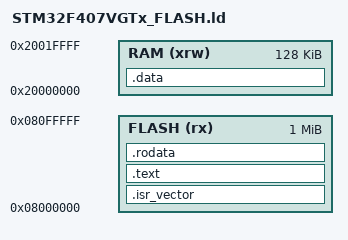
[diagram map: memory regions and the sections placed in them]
/*
******************************************************************************
**

**  File        : LinkerScript.ld
**
**  Author		: Auto-generated by System Workbench for STM32
**
**  Abstract    : Linker script for STM32F407VGTx series
**                1024Kbytes FLASH and 192Kbytes RAM
**
**                Set heap size, stack size and stack location according
**                to application requirements.
**
**                Set memory bank area and size if external memory is used.
**
**  Target      : STMicroelectronics STM32
**
**  Distribution: The file is distributed “as is,” without any warranty
**                of any kind.
**
*****************************************************************************
** @attention
**
** <h2><center>&copy; COPYRIGHT(c) 2020 Jonathan Dukes, jdukes@tcd.ie</center></h2>
** <h2><center>&copy; COPYRIGHT(c) 2019 STMicroelectronics</center></h2>
**
** Redistribution and use in source and binary forms, with or without modification,
** are permitted provided that the following conditions are met:
**   1. Redistributions of source code must retain the above copyright notice,
**      this list of conditions and the following disclaimer.
**   2. Redistributions in binary form must reproduce the above copyright notice,
**      this list of conditions and the following disclaimer in the documentation
**      and/or other materials provided with the distribution.
**   3. Neither the name of STMicroelectronics nor the names of its contributors
**      may be used to endorse or promote products derived from this software
**      without specific prior written permission.
**
** THIS SOFTWARE IS PROVIDED BY THE COPYRIGHT HOLDERS AND CONTRIBUTORS "AS IS"
** AND ANY EXPRESS OR IMPLIED WARRANTIES, INCLUDING, BUT NOT LIMITED TO, THE
** IMPLIED WARRANTIES OF MERCHANTABILITY AND FITNESS FOR A PARTICULAR PURPOSE ARE
** DISCLAIMED. IN NO EVENT SHALL THE COPYRIGHT HOLDER OR CONTRIBUTORS BE LIABLE
** FOR ANY DIRECT, INDIRECT, INCIDENTAL, SPECIAL, EXEMPLARY, OR CONSEQUENTIAL
** DAMAGES (INCLUDING, BUT NOT LIMITED TO, PROCUREMENT OF SUBSTITUTE GOODS OR
** SERVICES; LOSS OF USE, DATA, OR PROFITS; OR BUSINESS INTERRUPTION) HOWEVER
** CAUSED AND ON ANY THEORY OF LIABILITY, WHETHER IN CONTRACT, STRICT LIABILITY,
** OR TORT (INCLUDING NEGLIGENCE OR OTHERWISE) ARISING IN ANY WAY OUT OF THE USE
** OF THIS SOFTWARE, EVEN IF ADVISED OF THE POSSIBILITY OF SUCH DAMAGE.
**
*****************************************************************************
*/

ENTRY(Reset_Handler)

_estack = 0x20020000;       /* end of RAM */
_Min_Stack_Size = 0x400;    /* required amount of stack */

MEMORY
{
RAM (xrw)       : ORIGIN = 0x20000000, LENGTH = 128K
FLASH (rx)      : ORIGIN = 0x08000000, LENGTH = 1024K
}

SECTIONS
{
  /* The startup code goes first into FLASH */
  .isr_vector :
  {
    . = ALIGN(4);
    KEEP(*(.isr_vector))
    . = ALIGN(4);
  } >FLASH

  /* The program code and other data goes into FLASH */
  .text :
  {
    . = ALIGN(4);
    *(.text)           /* .text sections (code) */
    . = ALIGN(4);
    _etext = .;        /* define a global symbols at end of code */
  } >FLASH

  /* Constant data goes into FLASH */
  .rodata :
  {
    . = ALIGN(4);
    *(.rodata)         /* .rodata sections (constants, strings, etc.) */
    . = ALIGN(4);
  } >FLASH
  
  /* Uninitialized data section */
  .data :
  {
    . = ALIGN(4);
    *(.data)
    . = ALIGN(4);
  } >RAM
}


